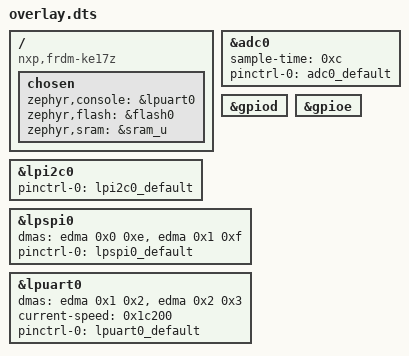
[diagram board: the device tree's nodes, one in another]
/ {
	compatible = "nxp,frdm-ke17z", "nxp,ke17z", "nxp,mke17z7";
	chosen {
		zephyr,console = &lpuart0;
		zephyr,flash = &flash0;
		zephyr,sram = &sram_u;
	};
};
&adc0{
	status = "okay";
	sample-time = < 0xc >;
	pinctrl-0 = < &adc0_default >;
	pinctrl-names = "default";
};
&gpiod{
	status = "okay";
};
&gpioe{
	status = "okay";
};
&lpi2c0{
	status = "okay";
	pinctrl-0 = < &lpi2c0_default >;
	pinctrl-names = "default";
};
&lpspi0{
	status = "okay";
	dmas = < &edma 0x0 0xe >, < &edma 0x1 0xf >;
	dma-names = "rx", "tx";
	pinctrl-0 = < &lpspi0_default >;
	pinctrl-names = "default";
};
&lpuart0{
	status = "okay";
	dmas = < &edma 0x1 0x2 >, < &edma 0x2 0x3 >;
	dma-names = "rx", "tx";
	current-speed = < 0x1c200 >;
	pinctrl-0 = < &lpuart0_default >;
	pinctrl-names = "default";
};
